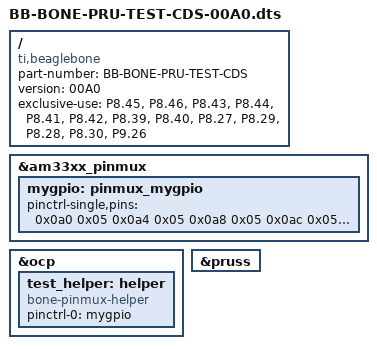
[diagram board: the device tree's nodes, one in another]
/*
* dts file BB-BONE-PRU-TEST-CDS-00A0.dts
*/
/dts-v1/;
/plugin/;

/ {
  compatible = "ti,beaglebone", "ti,beaglebone-black";

  /* identification */
  part-number = "BB-BONE-PRU-TEST-CDS";
  version = "00A0";

  exclusive-use =
    "P8.45",	/*pr_pru1_r31_0      (ADC_D0)  */
    "P8.46",	/*pr_pru1_r31_1      (ADC_D1)  */
    "P8.43",	/*pr_pru1_r31_2      (ADC_D2)  */
    "P8.44",	/*pr_pru1_r31_3      (ADC_D3)  */
    "P8.41",	/*pr_pru1_r31_4      (ADC_D4)  */
    "P8.42",	/*pr_pru1_r31_5      (ADC_D5)  */
    "P8.39",	/*pr_pru1_r31_6      (ADC_D6)  */
    "P8.40",	/*pr_pru1_r31_7      (ADC_D7)  */
    "P8.27",	/*pr_pru1_r31_8      (ADC_D8)  */
    "P8.29",	/*pr_pru1_r31_9      (ADC_D9)  */
    "P8.28",	/*pr_pru1_r31_10     (ADC_D10) */
    "P8.30",	/*pr_pru1_r31_11     (ADC_D11) */
    "P9.26";	/*pr_pru1_r31_16     (ADC_CLKIN)*/

  
  fragment@0 {
    target = <&am33xx_pinmux>;
    __overlay__ {
      mygpio: pinmux_mygpio{ 
        pinctrl-single,pins = < 
          0x0a0 0x05 /* lcd_data0.pr1_pru1_pru_r30_0       | slw-fst | O | PD | P-ud EN | MODE5 */
  	  0x0a4 0x05 /* lcd_data1.pr1_pru1_pru_r30_1       | slw-fst | O | PD | P-ud EN | MODE5 */
          0x0a8 0x05 /* lcd_data2.pr1_pru1_pru_r30_2       | slw-fst | O | PD | P-ud EN | MODE5 */
          0x0ac 0x05 /* lcd_data3.pr1_pru1_pru_r30_3       | slw-fst | O | PD | P-ud EN | MODE5 */
          0x0b0 0x05 /* lcd_data4.pr1_pru1_pru_r30_4       | slw-fst | O | PD | P-ud EN | MODE5 */
          0x0b4 0x05 /* lcd_data5.pr1_pru1_pru_r30_5       | slw-fst | O | PD | P-ud EN | MODE5 */
          0x0b8 0x05 /* lcd_data6.pr1_pru1_pru_r30_6       | slw-fst | O | PD | P-ud EN | MODE5 */
          0x0bc 0x05 /* lcd_data2.pr1_pru1_pru_r30_7       | slw-fst | O | PD | P-ud EN | MODE5 */
          0x0e0 0x05 /* lcd_vsync.pr1_pru1_pru_r30_8       | slw-fst | O | PD | P-ud EN | MODE5 */
          0x0e4 0x05 /* lcd_hsync.pr1_pru1_pru_r30_9       | slw-fst | O | PD | P-ud EN | MODE5 */
          0x0e8 0x05 /* lcd_pclk.pr1_pru1_pru_r30_10       | slw-fst | O | PD | P-ud EN | MODE5 */
          0x0ec 0x05 /* lcd_ac_bias_en.pr1_pru1_pru_r30_11 | slw-fst | O | PD | P-ud EN | MODE5 */
          0x180 0x05 /* uart1_rxd.pr1_pru1_pru_r30_16      | slw-fst | O | PD | P-ud EN | MODE5 */
          >;

      };
    };
  };

  fragment@1 {
    target = <&ocp>;
    __overlay__ {
      test_helper: helper {
        compatible = "bone-pinmux-helper";
        pinctrl-names = "default";
        pinctrl-0 = <&mygpio>;
        status = "okay";
      };
    };
  };

  fragment@2{
  target = <&pruss>;
    __overlay__ {
      status = "okay";
    };
  };
};
